# YTM32B1MD2 register map
Vendor: YTMicro; File version: 1.0
CPU: CM33 r0p4, little endian, MPU, FPU, 2 interrupt priority bits
Registers are 32-bit, read-write, reset 0x0 unless marked. A register's access mark holds for its fields unless they carry their own. Offsets are from the block's base; [hi:lo] are bit positions; {n}, {i} and the like mark numbered series; 'fields as' and 'values as' point back to an identical list.

## I2C0 — Inter-Integrated Circuit
Base 0x40023000; register names take the prefix I2C0_
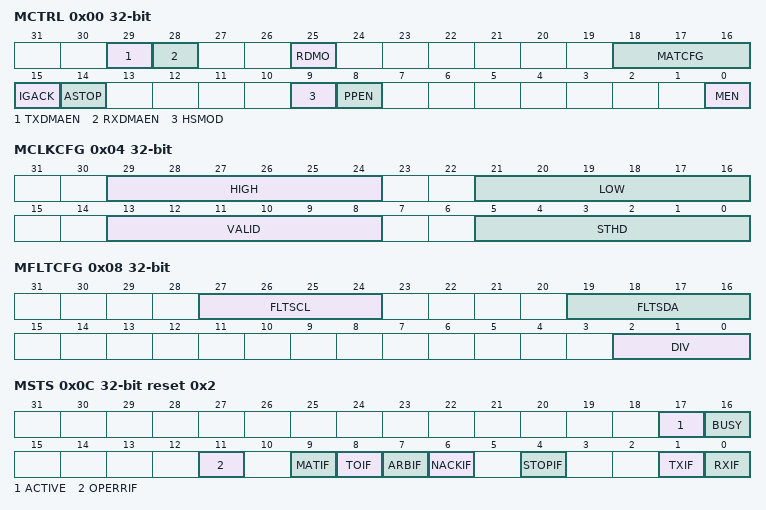
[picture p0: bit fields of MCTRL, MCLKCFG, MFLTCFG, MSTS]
0x00 MCTRL
  [29] TXDMAEN — TX DATA request DMA enable when TX fifo less than watermark or buff empty
    0=DMA request disabled; 1=DMA request enabled
  [28] RXDMAEN — RX DATA request DMA enable when RX fifo great than watermark or buff full
    0=DMA request disabled; 1=DMA request enabled
  [25] RDMO — Setting this bit will set I2C only stores data after received matched match configuration
    0=I2C will store all received data; 1=I2C will only store data after data matched
  [18:16] MATCFG — I2C match feature configuration
    0=Match disabled; 2=First data match MATCH0 or MATCH1; 3=Any data match MATCH0 or MATCH1; 4=First data match MATCH0 and second data match MATCH1; 5=Any data match MATCH0 and next data match MATCH1; 6=First data byte AND with MATCH1 match MATCH0; 7=Any data byte AND with MATCH1 match MATCH0
  [15] IGACK — Setting this bit will let I2C generate internal ACK even if NACK received. ewline ote{This bit should be set in Ultra-Fast mode.}
    0=I2C will receive ACK and NACK normally; 1=I2C will treat received NACK as ACK
  [14] ASTOP — Setting this bit will let I2C automatically generate STOP condition when TX FIFO empty
    0=I2C master generated STOP with STOP command; 1=I2C master generated STOP with STOP command or TX FIFO is empty
  [9] HSMOD — Setting this bit will let I2C working under High-Speed mode(only support data output)
    0=I2C under normal mode; 1=I2C in High-Speed output only mode
  [8] PPEN — Setting this bit will let I2C SCL/SDA to push-pull mode
    0=SCL/SDA in open drain mode; 1=SCL/SDA in push pull mode
  [0] MEN — Control all I2C master logic
    0=Master mode is disabled; 1=Master mode is enabled
0x04 MCLKCFG — MCLK register not support update when master logic is enabled
  [29:24] HIGH — Minimum number of cycles (minus one) that the SCL clock is driven high by the master. The SCL high time is extended by the time it takes to detect a rising edge on the external SCL pin. Ignoring any additional board delay due to external loading, this time is equal to (2 + FLTSCL) / 2^DIV cycles.
  [21:16] LOW — Minimum number of cycles (minus one) that the SCL clock is driven low by the master. The SCL low period value is also used for the minimum bus free time between a STOP and a START condition; this is extended by the time it takes to detect a rising edge on the external SCL pin. Ignoring any additional board delay due to external loading, this time is equal to (2 + FLTSCL) / 2^DIV cycles.
  [13:8] VALID — SDA data valid period is (VALID + 1) * divided clock period
  [5:0] STHD — SDA data setup/hold period is (STHD + 1) * divided clock period
0x08 MFLTCFG — FLTDIV register not support update when master logic is enabled
  [27:24] FLTSCL — Control digital filter on SCL line ewline SCL digital filter use undivided I2C function clock ewline Noise less or equal FLTSCL * function period will be filtered
  [19:16] FLTSDA — Control digital filter on SDA line ewline SDA digital filter use undivided I2C function clock ewline Noise less or equal FLTSDA * function period will be filtered
  [2:0] DIV — Control I2C master logic clock divider
    0=I2C master clock divided by 1; 1=I2C master clock divided by 2; 2=I2C master clock divided by 4; 3=I2C master clock divided by 8; 4=I2C master clock divided by 16; 5=I2C master clock divided by 32; 6=I2C master clock divided by 64; 7=I2C master clock divided by 128
0x0C MSTS reset 0x2
  [17] ACTIVE ro — I2C master is transmitting or receiving data
    0=I2C master is idle; 1=I2C master is busy
  [16] BUSY ro — I2C Bus is transmitting or receiving data
    0=I2C bus is idle; 1=I2C bus is busy
  [11] OPERRIF — I2C master operation error for detecting an attempt to send or receive data without first generating a (repeated) START condition. This bit is set if TX FIFO underflows. And it does not automatically generate a STOP. ewline User have to clear this bit before start a new data transfer
  [9] MATIF — Indicates I2C master received data matched data match configuration
    0=Received data not matched; 1=Received data matched
  [8] TOIF — This bit set when line low timeout detection enable and SCL/SDA low timeout ewline This bit only cleared when SCL/SDA line return to 1 ewline User have to solve pin low error before start a new data transfer
    0=Line low timeout not detected; 1=Line low timeout detected
  [7] ARBIF — This bit is set when ewline Master send out logic 1 but detect logic 0 on SCL or SDA line ewline Master detected START or STOP condition on bus ewline User have to clear this bit before start a new data transfer
    0=I2C master working normal; 1=I2C master lost arbitration
  [6] NACKIF — If ACK detected logic is enable (IGACK is cleared), I2C master will send out STOP and terminate current transfer, NACKIF bit will set.
    0=I2C master working normal; 1=I2C master detected NACK
  [4] STOPIF — Set when I2C master send out a STOP condition successfully
    0=I2C master not generated STOP; 1=I2C master generated STOP
  [1] TXIF ro — Indicates words in TX FIFO is equal or less than TX FIFO watermark setting
    0=Word in TX FIFO is greater than watermark; 1=Word in TX FIFO is equal or less than watermark, request to write new data
  [0] RXIF ro — Indicates words in RX FIFO is greater than RX FIFO watermark setting
    0=Word in RX FIFO is equal or less than watermark; 1=Word in RX FIFO is greater than watermark, should read data register
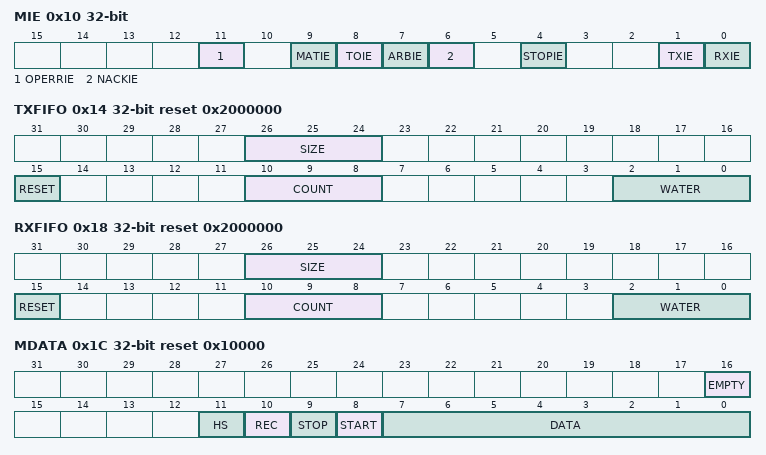
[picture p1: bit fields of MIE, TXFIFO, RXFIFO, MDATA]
0x10 MIE
  [all] fields
    0=Interrupt disabled; 1=Interrupt enabled
  [11] OPERRIE
  [9] MATIE
  [8] TOIE
  [7] ARBIE
  [6] NACKIE
  [4] STOPIE
  [1] TXIE
  [0] RXIE
0x14 TXFIFO reset 0x2000000
  [26:24] SIZE ro — Available TX FIFO Size is 2^SIZE words. SIZE reads as 2.
  [15] RESET wo — Reset TX FIFO address pointer
  [10:8] COUNT ro — I2C Master TX FIFO current data count
  [2:0] WATER — TXIF set when words count in TX FIFO equal or less than watermark
0x18 RXFIFO reset 0x2000000
  [26:24] SIZE ro — Available RX FIFO Size is 2^SIZE words. SIZE reads as 2.
  [15] RESET wo — Reset I2C master RX FIFO address pointer
  [10:8] COUNT ro — Current data count in RX FIFO
  [2:0] WATER — RXIF set when words count in RX FIFO greater than watermark
0x1C MDATA reset 0x10000 — Write MDATA will let I2C master send out address/data/repeat start/stop to I2C bus and read MDATA will return I2C master received data and status.
  [16] EMPTY ro — RX FIFO or buffer is empty
  [11] HS wo — Setting this bit will let I2C master send data in high speed mode
  [10] REC wo — Setting this bit with target bytes count in DATA field will let I2C receive (DATA + 1) bytes data
  [9] STOP wo — Setting this bit with slave address in DATA field will let I2C master send STOP to given slave
  [8] START wo — Setting this bit with slave address in DATA field will let I2C master generate START/repeat START to given slave
  [7:0] DATA — Write DATA will let I2C master send out data or address ewline Read DATA will return I2C master received data in FIFO or buffer
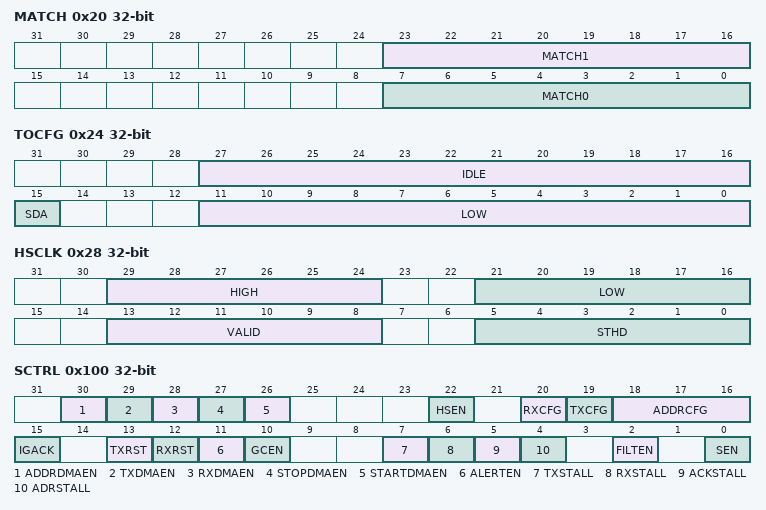
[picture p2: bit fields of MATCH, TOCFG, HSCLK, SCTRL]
0x20 MATCH
  [23:16] MATCH1 — Store the data 1 for match comparison
  [7:0] MATCH0 — Store the data 0 for match comparison
0x24 TOCFG
  [27:16] IDLE — Line idle flag set when SDA and SCL line high for (IDLE) * divided function clock, after line idle, master can send out START.
  [15] SDA — Set this bit to enable SDA line low detection
    0=Line low only detect SCL; 1=Line low detect SDA and SCL
  [11:0] LOW — Line low period is (LOW * 256) * divided function clock
0x28 HSCLK
  fields as MCLKCFG
0x100 SCTRL
  [30] ADDRDMAEN — Control weather DMA request generated after a valid address received
    0=DMA request disabled; 1=DMA request enabled
  [29] TXDMAEN — TX DATA request DMA enable when TX buff empty
    0=DMA request disabled; 1=DMA request enabled
  [28] RXDMAEN — RX DATA request DMA enable when RX buff full
    0=DMA request disabled; 1=DMA request enabled
  [27] STOPDMAEN — Control weather DMA request generated after a STOP condition received
    0=DMA request disabled; 1=DMA request enabled
  [26] STARTDMAEN — Control weather DMA request generated after a START condition received
    0=DMA request disabled; 1=DMA request enabled
  [22] HSEN — Setting this bit enables I2C salve high speed address match and switch enable
    0=Disable high speed mode switch; 1=Enable high speed mode switch
  [20] RXCFG — Controls weather address include in reading RX data register
    0=Reading RX data register will only return received data and clear RX data flag; 1=Reading RX data register will only return received address when valid address mode flag set, and clear address valid flag. ewline Reading RX data when address valid flag clear will return received data and clear RX data flag
  [19] TXCFG — Controls weather TX data flag asserted when I2C slave idle
    0=TX data flag only asserted when I2C active and TX buffer empty; 1=TX data flag asserted when TX buffer empty
  [18:16] ADDRCFG — Control slave address match configuration
    0=Address match 0 (7-bit); 1=Address match 0 (10-bit); 2=Address match 0 (7-bit) or match 1(7-bit); 3=Address match 0 (10-bit) or match 1(10-bit); 4=Address match 0 (7-bit) or match 1(10-bit); 5=Address match 0 (10-bit) or match 1(7-bit); 6=Address match from match 0 (7-bit) to match 1(7-bit); 7=Address match from match 0 (10-bit) to match 1(10-bit)
  [15] IGACK — Setting this bit will let I2C generate internal ACK even if NACK received. ewline ote{This bit should be set in Ultra-Fast mode.}
    values as MCTRL.IGACK
  [13] TXRST wo — Reset TX buffer pointer
    0=No effect; 1=Reset TX buffer pointer
  [12] RXRST wo — Reset RX buffer pointer
    0=No effect; 1=Reset RX buffer pointer
  [11] ALERTEN — Setting this bit will let I2C slave set SMBus alert address(0001100xb) as a match condition
    0=Alert address detect is disabled; 1=Alert address detect is enabled
  [10] GCEN — Setting this bit will let I2C slave set general call address(0000000xb) as a match condition
    0=General call address detect is disabled; 1=General call address detect is enabled
  [7] TXSTALL — Enables I2C slave stretching SCL line to low when slave TX buffer is empty
    0=Slave stretching is disabled; 1=Slave stretching is enabled
  [6] RXSTALL — Enables I2C slave stretching SCL line to low when slave RX buffer is full
    values as TXSTALL
  [5] ACKSTALL — Enables I2C slave stretching SCL line to low when slave waiting for software write ACK register ewline ote{Setting ACKSTALL will set RXSTALL and ADRSTALL automatically.}
    values as TXSTALL
  [4] ADRSTALL — Enables I2C slave stretching SCL line to low when valid address received but not read
    values as TXSTALL
  [2] FILTEN — Slave digital filter not update when I2C slave enabled
    0=Digital filter is disabled; 1=Digital filter is enabled
  [0] SEN — Setting this bit will enable I2C slave logic
    0=Slave module is disabled; 1=Slave module is enabled
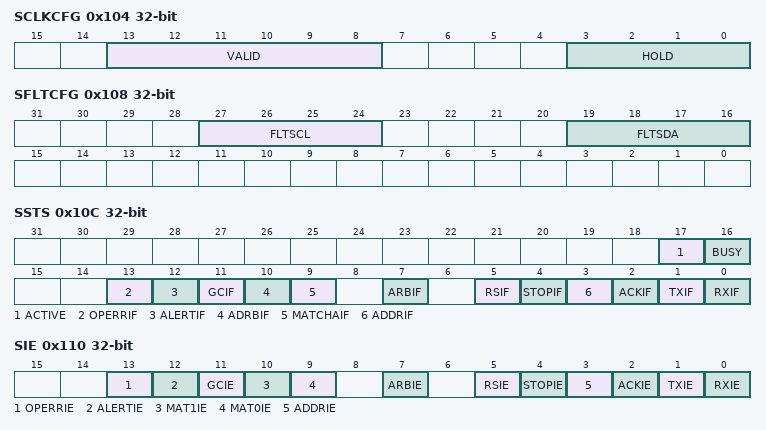
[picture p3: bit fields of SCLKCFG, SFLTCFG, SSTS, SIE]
0x104 SCLKCFG
  [13:8] VALID — SDA data delay is (FILTSCL + VALID + 3) function clock (not divided clock)
  [3:0] HOLD — Data hold delay is (HOLD + 3) function clock (not divided clock)
0x108 SFLTCFG
  [27:24] FLTSCL — Control digital filter on SCL line ewline SCL digital filter use undivided I2C function clock ewline Noise less or equal FLTSCL * function period will be filtered
  [19:16] FLTSDA — Control digital filter on SDA line ewline SDA digital filter use undivided I2C function clock ewline Noise less or equal FLTSDA * function period will be filtered
0x10C SSTS
  [17] ACTIVE ro — I2C slave is transmitting or receiving data
    0=I2C slave is idle; 1=I2C slave is busy
  [16] BUSY ro — I2C Bus is transmitting or receiving data
    0=I2C bus is idle; 1=I2C bus is busy
  [13] OPERRIF — I2C slave operation error, this bit is set when \begin{itemize}[] \item Slave need to send data when TX buffer empty and TXSTALL not enabled \item Slave received new data when RX buffer is full and RXSTALL not enabled \item Slave received new address when address already valid but not read and ADRSTALL is not enabled \vspace*{-\baselineskip} \end{itemize}
  [12] ALERTIF ro
    0=Alert address not received; 1=Alert address received
  [11] GCIF ro
    0=General call address not received; 1=General call address received
  [10] ADRBIF ro — Slave received address match address B flag
    0=Address B not received; 1=Address B received
  [9] MATCHAIF ro — Slave received address match address A flag
    0=Address A not received; 1=Address A received
  [7] ARBIF — This bit is set when ewline Slave send out logic 1 but detect logic 0 on SCL or SDA line ewline Slave will ignore following transfer until new (repeat) START received
    0=I2C slave working normal; 1=I2C slave lost arbitration
  [5] RSIF — Repeat start set when I2C received a repeat START and previous address matched
    0=I2C slave not received repeat start; 1=I2C slave received repeat start
  [4] STOPIF — Stop interrupt set when I2C already addressed and received a stop condition
    0=I2C slave not received STOP; 1=I2C slave received STOP
  [3] ADDRIF ro — Address valid set when address match received and cleared after read address register or read DATA register when RXCFG bit set
    0=I2C slave not received any valid address; 1=I2C slave received a valid address
  [2] ACKIF ro — Ack request set when slave need to send ACK or NACK to master, this bit cleared by write ACK register
    0=I2C slave don't need to send ACK or NACK to master; 1=I2C slave need to send ACK or NACK to master
  [1] TXIF ro — Indicates words in TX FIFO is equal or less than TX FIFO watermark setting
    values as MSTS.TXIF
  [0] RXIF ro — Indicates words in RX FIFO is greater than RX FIFO watermark setting
    values as MSTS.RXIF
0x110 SIE
  [all] fields
    0=Interrupt disabled; 1=Interrupt enabled
  [13] OPERRIE
  [12] ALERTIE
  [11] GCIE
  [10] MAT1IE
  [9] MAT0IE
  [7] ARBIE
  [5] RSIE
  [4] STOPIE
  [3] ADDRIE
  [2] ACKIE
  [1] TXIE
  [0] RXIE
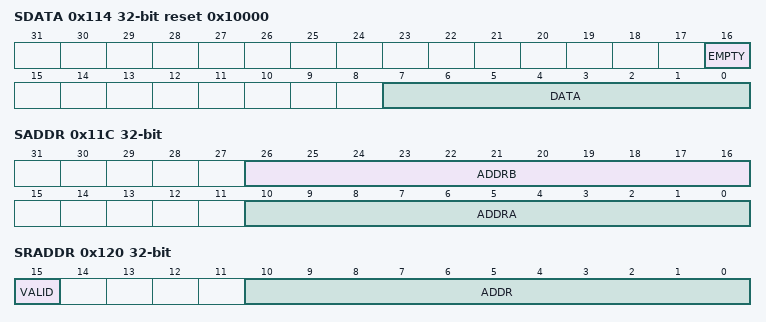
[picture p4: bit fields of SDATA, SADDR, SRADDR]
0x114 SDATA reset 0x10000
  [16] EMPTY ro
    0=RX buffer is not empty; 1=RX buffer is empty
  [7:0] DATA — Write will push data to TX buffer and read will return received data or address
0x118 SACK
  [0] NACK — After slave received data, software can write NACK with 1 to send NACK or 0 to send ACK
    0=Send ACK; 1=Send NACK
0x11C SADDR
  [26:16] ADDRB — Store the address B for match comparison. The lowest bit (bit16) is readonly and only can be 0. The slave address truely used by protocol starts from bit17.
  [10:0] ADDRA — Store the address A for match comparison. The lowest bit (bit0) is readonly and only can be 0. The slave address truely used by protocol starts from bit1.
0x120 SRADDR ro
  [15] VALID rw
    0=Slave address is not valid; 1=Slave address is valid
  [10:0] ADDR rw — Store the slave received address

## I2C1 — Inter-Integrated Circuit
Base 0x40024000; register names take the prefix I2C1_
Registers as I2C0.
